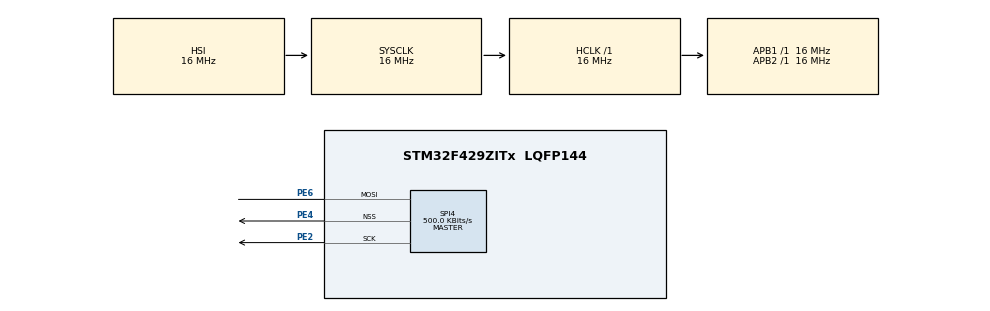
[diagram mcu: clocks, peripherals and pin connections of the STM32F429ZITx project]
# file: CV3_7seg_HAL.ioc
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Mcu.Family=STM32F4
Mcu.Name=STM32F429ZITx
Mcu.Package=LQFP144
NVIC.PriorityGroup=NVIC_PRIORITYGROUP_4
PE2.Mode=Simplex_Bidirectional_Master
PE2.Signal=SPI4_SCK
PE4.Mode=NSS_Signal_Hard_Output
PE4.Signal=SPI4_NSS
PE6.Mode=Simplex_Bidirectional_Master
PE6.Signal=SPI4_MOSI
ProjectManager.HeapSize=0x200
ProjectManager.StackSize=0x400
ProjectManager.TargetToolchain=STM32CubeIDE
RCC.AHBFreq_Value=16000000
RCC.APB1Freq_Value=16000000
RCC.APB2Freq_Value=16000000
RCC.CortexFreq_Value=16000000
RCC.HSE_VALUE=25000000
RCC.HSI_VALUE=16000000
RCC.LSE_VALUE=32768
RCC.SYSCLKFreq_VALUE=16000000
RCC.VCOOutputFreq_Value=192000000
SPI4.BaudRatePrescaler=SPI_BAUDRATEPRESCALER_32
SPI4.CalculateBaudRate=500.0 KBits/s
SPI4.DataSize=SPI_DATASIZE_16BIT
SPI4.Direction=SPI_DIRECTION_1LINE
SPI4.Mode=SPI_MODE_MASTER
SPI4.VirtualNSS=VM_NSSHARD
SPI4.VirtualType=VM_MASTER
board=custom

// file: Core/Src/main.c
/* USER CODE BEGIN Header */
/**
  ******************************************************************************
  * @file           : main.c
  * @brief          : Main program body
  ******************************************************************************
  * @attention
  *
  * <h2><center>&copy; Copyright (c) 2020 STMicroelectronics.
  * All rights reserved.</center></h2>
  *
  * This software component is licensed by ST under BSD 3-Clause license,
  * the "License"; You may not use this file except in compliance with the
  * License. You may obtain a copy of the License at:
  *                        opensource.org/licenses/BSD-3-Clause
  *
  ******************************************************************************
  */
/* USER CODE END Header */

#include "main.h"

/* USER CODE BEGIN Includes */
#include "max7219.h"
/* USER CODE END Includes */

SPI_HandleTypeDef hspi4;

void SystemClock_Config(void);
static void MX_GPIO_Init(void);
static void MX_SPI4_Init(void);

/* USER CODE BEGIN 0 */
void show(uint32_t value) {
	value %= 10000;
	uint32_t a = value / 1000;
	value -= a * 1000;
	uint32_t b = value / 100;
	value -= b * 100;
	uint32_t c = value / 10;
	value -= c * 10;
	uint32_t d = value;

	max7219_led(
			max7219_customRegValues[a] << 24 |
			max7219_customRegValues[b] << 16 |
			max7219_customRegValues[c] << 8 |
			max7219_customRegValues[d]);
}
/* USER CODE END 0 */

int main(void)
{

  /* MCU Configuration--------------------------------------------------------*/

  /* Reset of all peripherals, Initializes the Flash interface and the Systick. */
  HAL_Init();

  /* Configure the system clock */
  SystemClock_Config();

  /* Initialize all configured peripherals */
  MX_GPIO_Init();
  MX_SPI4_Init();
  /* USER CODE BEGIN 2 */
  max7219_init(0); // Init, do not use internal decode table
  /* USER CODE END 2 */

  /* Infinite loop */
  /* USER CODE BEGIN WHILE */
  while (1)
  {
	while(1) {
		static uint32_t i = 0;
		show(i);
		i += 111;
		if(i > 1000)
			i = 0;
		HAL_Delay(250);
	}
    /* USER CODE END WHILE */

  }
}

void SystemClock_Config(void)
{
  RCC_OscInitTypeDef RCC_OscInitStruct = {0};
  RCC_ClkInitTypeDef RCC_ClkInitStruct = {0};

  /** Configure the main internal regulator output voltage
  */
  __HAL_RCC_PWR_CLK_ENABLE();
  __HAL_PWR_VOLTAGESCALING_CONFIG(PWR_REGULATOR_VOLTAGE_SCALE3);
  /** Initializes the CPU, AHB and APB busses clocks
  */
  RCC_OscInitStruct.OscillatorType = RCC_OSCILLATORTYPE_HSI;
  RCC_OscInitStruct.HSIState = RCC_HSI_ON;
  RCC_OscInitStruct.HSICalibrationValue = RCC_HSICALIBRATION_DEFAULT;
  RCC_OscInitStruct.PLL.PLLState = RCC_PLL_NONE;
  if (HAL_RCC_OscConfig(&RCC_OscInitStruct) != HAL_OK)
  {
    Error_Handler();
  }
  /** Initializes the CPU, AHB and APB busses clocks
  */
  RCC_ClkInitStruct.ClockType = RCC_CLOCKTYPE_HCLK|RCC_CLOCKTYPE_SYSCLK
                              |RCC_CLOCKTYPE_PCLK1|RCC_CLOCKTYPE_PCLK2;
  RCC_ClkInitStruct.SYSCLKSource = RCC_SYSCLKSOURCE_HSI;
  RCC_ClkInitStruct.AHBCLKDivider = RCC_SYSCLK_DIV1;
  RCC_ClkInitStruct.APB1CLKDivider = RCC_HCLK_DIV1;
  RCC_ClkInitStruct.APB2CLKDivider = RCC_HCLK_DIV1;

  if (HAL_RCC_ClockConfig(&RCC_ClkInitStruct, FLASH_LATENCY_0) != HAL_OK)
  {
    Error_Handler();
  }
}

static void MX_SPI4_Init(void)
{

  /* SPI4 parameter configuration*/
  hspi4.Instance = SPI4;
  hspi4.Init.Mode = SPI_MODE_MASTER;
  hspi4.Init.Direction = SPI_DIRECTION_1LINE;
  hspi4.Init.DataSize = SPI_DATASIZE_16BIT;
  hspi4.Init.CLKPolarity = SPI_POLARITY_LOW;
  hspi4.Init.CLKPhase = SPI_PHASE_1EDGE;
  hspi4.Init.NSS = SPI_NSS_HARD_OUTPUT;
  hspi4.Init.BaudRatePrescaler = SPI_BAUDRATEPRESCALER_32;
  hspi4.Init.FirstBit = SPI_FIRSTBIT_MSB;
  hspi4.Init.TIMode = SPI_TIMODE_DISABLE;
  hspi4.Init.CRCCalculation = SPI_CRCCALCULATION_DISABLE;
  hspi4.Init.CRCPolynomial = 10;
  if (HAL_SPI_Init(&hspi4) != HAL_OK)
  {
    Error_Handler();
  }

}

static void MX_GPIO_Init(void)
{

  /* GPIO Ports Clock Enable */
  __HAL_RCC_GPIOE_CLK_ENABLE();

}

void Error_Handler(void)
{
}

/************************ (C) COPYRIGHT STMicroelectronics *****END OF FILE****/
